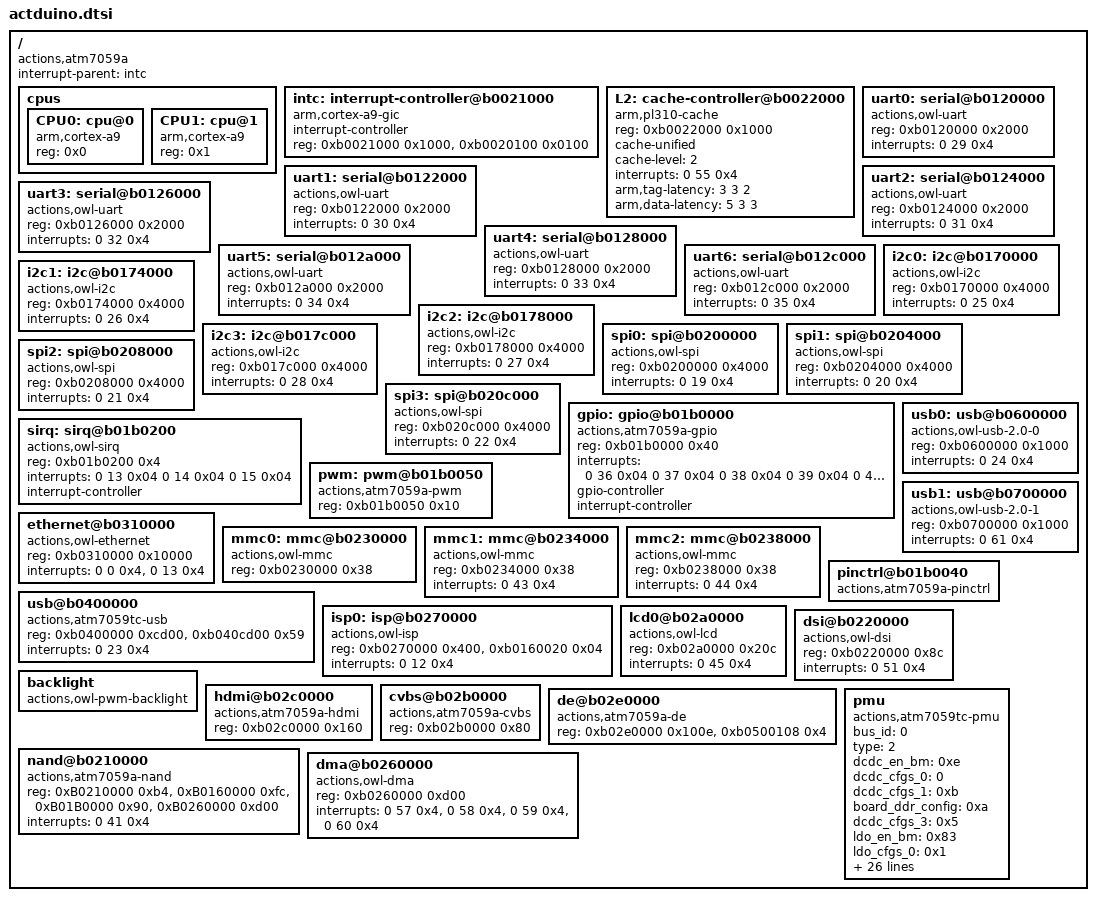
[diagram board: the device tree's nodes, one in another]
/include/ "skeleton.dtsi"

/ {
	compatible = "actions,atm7059a";
	interrupt-parent = <&intc>;

	cpus {
		#size-cells = <0>;
		#address-cells = <1>;

		CPU0: cpu@0 {
			device_type = "cpu";
			compatible = "arm,cortex-a9";
			reg = <0x0>;
		};

		CPU1: cpu@1 {
			device_type = "cpu";
			compatible = "arm,cortex-a9";
			reg = <0x1>;
		};
	};

	/* look at binding Documentation/devicetree/bindings/arm/gic.txt */
	intc: interrupt-controller@b0021000 {
		compatible = "arm,cortex-a9-gic";
		interrupt-controller;
		#interrupt-cells = <3>;
		reg = < 0xb0021000 0x1000 >,
		      < 0xb0020100 0x0100 >;
	};

	L2: cache-controller@b0022000 {
		compatible = "arm,pl310-cache";
		reg = < 0xb0022000 0x1000 >;
		cache-unified;
		cache-level = <2>;
		interrupts = < 0 55 0x4 >;
		arm,tag-latency = <3 3 2>;
		arm,data-latency = <5 3 3>;
	};

	uart0: serial@b0120000 {
		compatible = "actions,owl-uart", "actions,owl-uart-irc";
		reg = <0xb0120000 0x2000>;
		interrupts = < 0 29 0x4 >;
	};

	uart1: serial@b0122000 {
		compatible = "actions,owl-uart";
		reg = <0xb0122000 0x2000>;
		interrupts = < 0 30 0x4 >;
	};

	uart2: serial@b0124000 {
		compatible = "actions,owl-uart";
		reg = <0xb0124000 0x2000>;
		interrupts = < 0 31 0x4 >;
	};

	uart3: serial@b0126000 {
		compatible = "actions,owl-uart";
		reg = <0xb0126000 0x2000>;
		interrupts = < 0 32 0x4 >;
	};

	uart4: serial@b0128000 {
		compatible = "actions,owl-uart";
		reg = <0xb0128000 0x2000>;
		interrupts = < 0 33 0x4 >;
	};

	uart5: serial@b012a000 {
		compatible = "actions,owl-uart";
		reg = <0xb012a000 0x2000>;
		interrupts = < 0 34 0x4 >;
	};

	uart6: serial@b012c000 {
		compatible = "actions,owl-uart";
		reg = <0xb012c000 0x2000>;
		interrupts = < 0 35 0x4 >;
	};

	i2c0: i2c@b0170000 {
		#address-cells = <1>;
		#size-cells = <0>;
		compatible = "actions,owl-i2c";
		reg = <0xb0170000 0x4000>;
		interrupts = < 0 25 0x4 >;
	};

	i2c1: i2c@b0174000 {
		#address-cells = <1>;
		#size-cells = <0>;
		compatible = "actions,owl-i2c";
		reg = <0xb0174000 0x4000>;
		interrupts = < 0 26 0x4 >;
	};

	i2c2: i2c@b0178000 {
		#address-cells = <1>;
		#size-cells = <0>;
		compatible = "actions,owl-i2c";
		reg = <0xb0178000 0x4000>;
		interrupts = < 0 27 0x4 >;
	};

	i2c3: i2c@b017c000 {
		#address-cells = <1>;
		#size-cells = <0>;
		compatible = "actions,owl-i2c";
		reg = <0xb017c000 0x4000>;
		interrupts = < 0 28 0x4 >;
	};

	spi0: spi@b0200000 {
		#address-cells = <1>;
		#size-cells = <0>;
		compatible = "actions,owl-spi";
		reg = <0xb0200000 0x4000>;
		interrupts = < 0 19 0x4 >;
	};

	spi1: spi@b0204000 {
		#address-cells = <1>;
		#size-cells = <0>;
		compatible = "actions,owl-spi";
		reg = <0xb0204000 0x4000>;
		interrupts = < 0 20 0x4 >;
	};

	spi2: spi@b0208000 {
		#address-cells = <1>;
		#size-cells = <0>;
		compatible = "actions,owl-spi";
		reg = <0xb0208000 0x4000>;
		interrupts = < 0 21 0x4 >;
	};

	spi3: spi@b020c000 {
		#address-cells = <1>;
		#size-cells = <0>;
		compatible = "actions,owl-spi";
		reg = <0xb020c000 0x4000>;
		interrupts = < 0 22 0x4 >;
	};

	gpio: gpio@b01b0000 {
		compatible = "actions,atm7059a-gpio";
		reg = < 0xb01b0000 0x40 >;
		interrupts = <
			0 36 0x04 /* GPIOA */
			0 37 0x04 /* GPIOB */
			0 38 0x04 /* GPIOC */
			0 39 0x04 /* GPIOD */
			0 40 0x04 /* GPIOE */ >;
		#gpio-cells = <2>;
		gpio-controller;
		#interrupt-cells = <2>;
		interrupt-controller;
	};

	sirq: sirq@b01b0200 {
		compatible = "actions,owl-sirq";
		reg = < 0xb01b0200 0x4 >;
		interrupts = <
			0 13 0x04  /* SIRQ0 */
			0 14 0x04  /* SIRQ1 */
			0 15 0x04  /* SIRQ2 */ >;
		#interrupt-cells = <2>;
		interrupt-controller;
	};

	pwm: pwm@b01b0050 {
		compatible = "actions,atm7059a-pwm";
		reg = <0xb01b0050 0x10>;
		#pwm-cells = <3>;
	};

	ethernet@b0310000 {
		#address-cells = <1>;
		#size-cells = <0>;
		compatible = "actions,owl-ethernet";
		reg = <0xb0310000 0x10000>;
		interrupts = < 0 0 0x4 >, < 0 13 0x4 >;
	};

	mmc0: mmc@b0230000 {
		#address-cells = <1>;
		#size-cells = <0>;
		compatible = "actions,owl-mmc";
		reg = <0xb0230000 0x38>;
	};

	mmc1: mmc@b0234000 {
		#address-cells = <1>;
		#size-cells = <0>;
		compatible = "actions,owl-mmc";
		reg = <0xb0234000 0x38>;
		interrupts = < 0 43 0x4 >;
	};

	mmc2: mmc@b0238000 {
		#address-cells = <1>;
		#size-cells = <0>;
		compatible = "actions,owl-mmc";
		reg = <0xb0238000 0x38>;
		interrupts = < 0 44 0x4 >;
	};

	usb0: usb@b0600000 {
		#address-cells = <1>;
		#size-cells = <0>;
		compatible = "actions,owl-usb-2.0-0";
		reg = <0xb0600000 0x1000>;
		interrupts = < 0 24 0x4 >;
	};
	
	usb1: usb@b0700000 {
		#address-cells = <1>;
		#size-cells = <0>;
		compatible = "actions,owl-usb-2.0-1";
		reg = <0xb0700000 0x1000>;
		interrupts = < 0 61 0x4 >;
	};

	usb@b0400000 {
		#address-cells = <1>;
		#size-cells = <0>;
		compatible = "actions,atm7059tc-usb";
		reg = <0xb0400000 0xcd00>,
			  <0xb040cd00 0x59>;
		interrupts = < 0 23 0x4 >;
	};
    
	isp0: isp@b0270000 {
		#address-cells = <1>;
		#size-cells = <1>;
		compatible = "actions,owl-isp";
		reg = <0xb0270000 0x400>,<0xb0160020 0x04>;
		interrupts = < 0 12 0x4 >;
	};

	pinctrl@b01b0040 {
		compatible = "actions,atm7059a-pinctrl";
	};

	lcd0@b02a0000 {
		compatible = "actions,owl-lcd";
		reg = <0xb02a0000 0x20c>;
		interrupts = < 0 45 0x4 >;
	};

	dsi@b0220000 {
		compatible = "actions,owl-dsi";
		reg = <0xb0220000 0x8c>;
		interrupts = < 0 51 0x4 >;
	};

  	backlight {
		compatible = "actions,owl-pwm-backlight";
	};
	
	hdmi@b02c0000{
		compatible = "actions,atm7059a-hdmi";
		reg = <0xb02c0000 0x160>;
	};
	
	cvbs@b02b0000{
		compatible = "actions,atm7059a-cvbs";
		reg = <0xb02b0000 0x80>;
	};
	
	de@b02e0000 {
		compatible = "actions,atm7059a-de";
		reg = <0xb02e0000 0x100e>, <0xb0500108 0x4>;
	};
	
	nand@b0210000 {
		#address-cells = <1>;
		#size-cells = <1>;
		compatible = "actions,atm7059a-nand";
		reg = <0xB0210000 0xb4>, <0xB0160000 0xfc>, <0xB01B0000 0x90>, <0xB0260000 0xd00>;
		interrupts = < 0 41 0x4 >;
	};

	dma@b0260000 {
		compatible = "actions,owl-dma";
		reg = <0xb0260000 0xd00>;
		interrupts = < 0 57 0x4 >, < 0 58 0x4 >, < 0 59 0x4 >, < 0 60 0x4 >;
	};

	pmu {
		compatible = "actions,atm7059tc-pmu";
		bus_id = <0>;
		type = <2>;
		dcdc_en_bm = <0xe>;
		dcdc_cfgs_0 = <0>;
		dcdc_cfgs_1 = <0xb>;
		board_ddr_config = <0xa>;
		dcdc_cfgs_3= <0x5>;
		ldo_en_bm = <0x83>;
		ldo_cfgs_0 = <0x1>;
		ldo_cfgs_1 = <0x2>;
		ldo_cfgs_2 = <0>;
		ldo_cfgs_3 = <0>;
		ldo_cfgs_4 = <0>;
		ldo_cfgs_5 = <0>;
		ldo_cfgs_6 = <0>;
		ldo_cfgs_7 = <0x3>;
		ldo_cfgs_8 = <0>;
		ldo_cfgs_9 = <0>;
		ldo_cfgs_10 = <0>;
		ldo_cfgs_11 = <0>;
		pwm_config_0_pwm_val = <0>;
		pwm_config_0_shift = <0>;
		pwm_config_0_mask = <0>;
		pwm_config_0_val = <0>;
		pwm_config_0_no = <0>;
		pwm_config_1_pwm_val = <0x102c3f>;
		pwm_config_1_shift = <0x26>;
		pwm_config_1_mask = <0x7>;
		pwm_config_1_val = <0x3>;
		pwm_config_1_no = <0x1>;
		pwm_config_2_pwm_val = <0x10343f>;
		pwm_config_2_shift = <0x26>;
		pwm_config_2_mask = <0x7>;
		pwm_config_2_val = <0x3>;
		pwm_config_2_no = <0x1>;
	};
};
